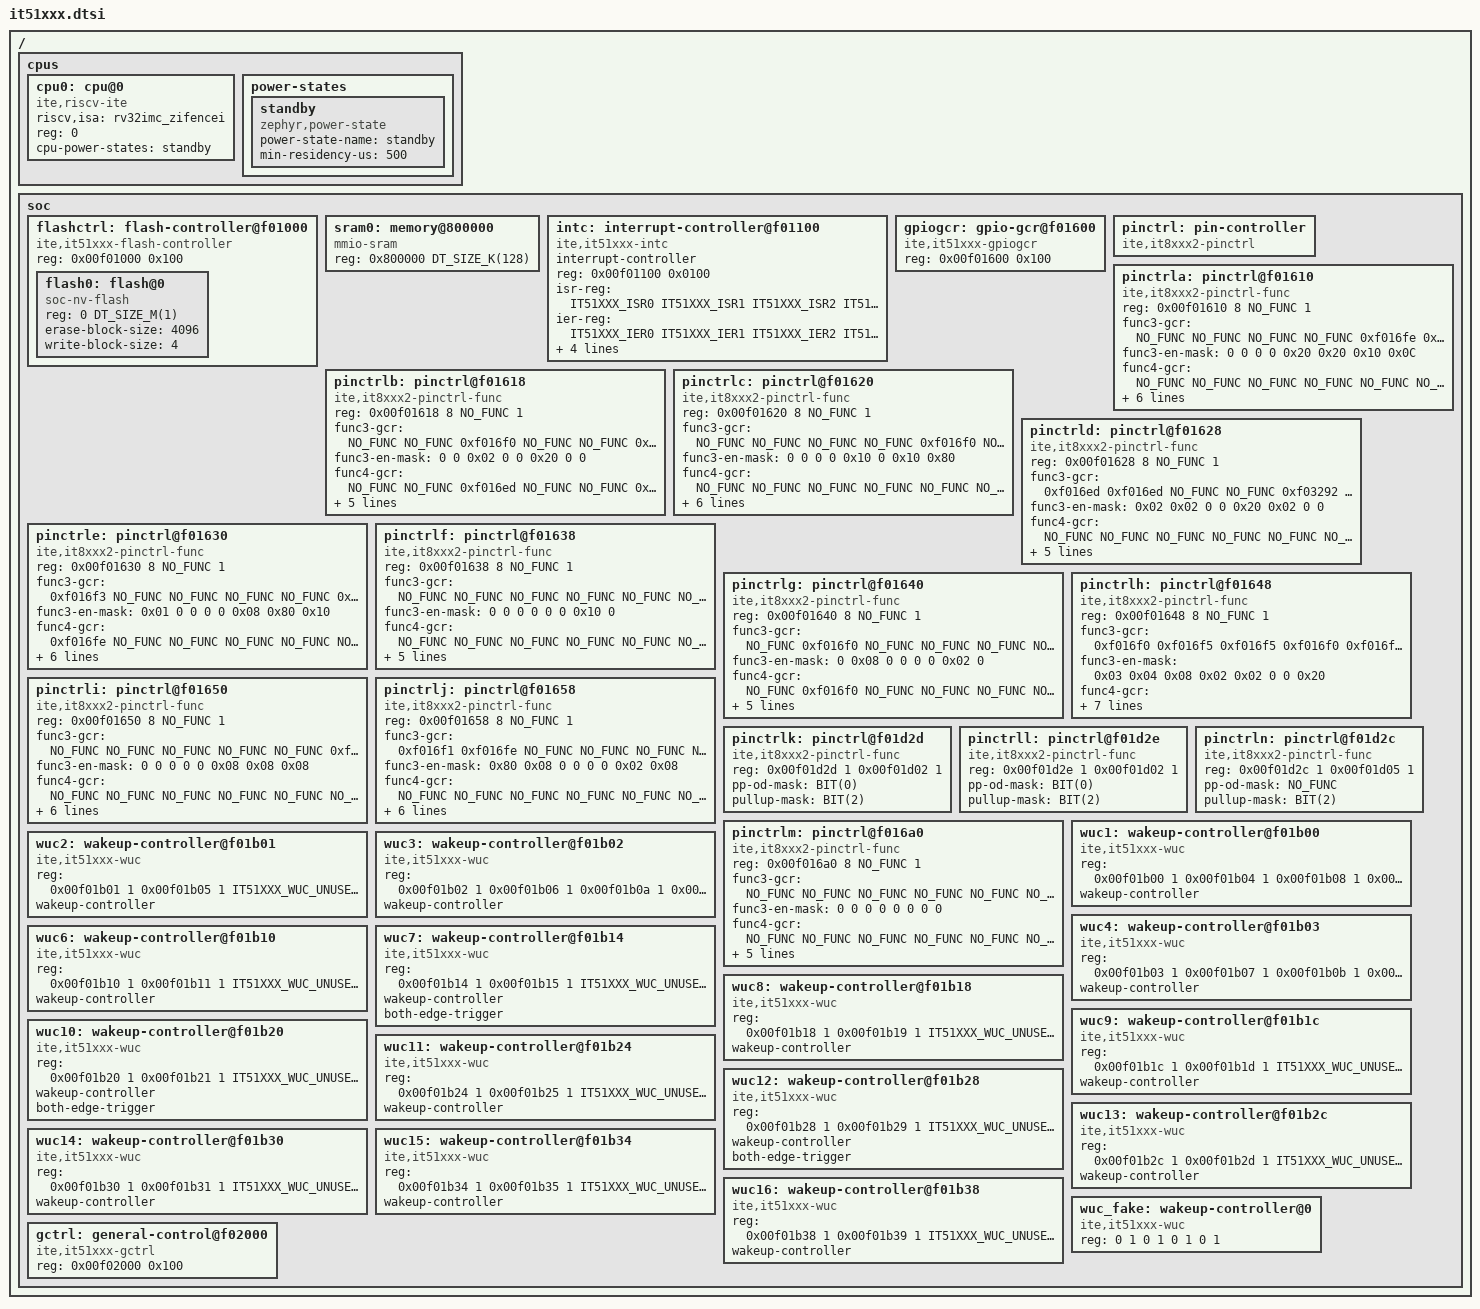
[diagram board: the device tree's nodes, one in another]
/*
 * Copyright (c) 2025 ITE Corporation. All Rights Reserved.
 *
 * SPDX-License-Identifier: Apache-2.0
 */

#include <ite/it51xxx-wuc-map.dtsi>
#include <mem.h>
#include <zephyr/dt-bindings/dt-util.h>
#include <zephyr/dt-bindings/interrupt-controller/ite-it51xxx-intc.h>
#include <zephyr/dt-bindings/interrupt-controller/ite-it51xxx-wuc.h>
#include <zephyr/dt-bindings/pinctrl/it8xxx2-pinctrl.h>

/ {
	#address-cells = <1>;
	#size-cells = <1>;

	cpus {
		#address-cells = <1>;
		#size-cells = <0>;
		cpu0: cpu@0 {
			compatible = "ite,riscv-ite", "riscv";
			riscv,isa = "rv32imc_zifencei";
			device_type = "cpu";
			reg = <0>;
			cpu-power-states = <&standby>;
		};

		power-states {
			standby: standby {
				compatible = "zephyr,power-state";
				power-state-name = "standby";
				min-residency-us = <500>;
			};
		};
	};

	soc {
		#address-cells = <1>;
		#size-cells = <1>;
		ranges;

		flashctrl: flash-controller@f01000 {
			compatible = "ite,it51xxx-flash-controller";
			reg = <0x00f01000 0x100>;
			#address-cells = <1>;
			#size-cells = <1>;

			flash0: flash@0 {
				compatible = "soc-nv-flash";
				reg = <0 DT_SIZE_M(1)>;
				erase-block-size = <4096>;
				write-block-size = <4>;
			};
		};

		sram0: memory@800000 {
			compatible = "mmio-sram";
			reg = <0x800000 DT_SIZE_K(128)>;
		};

		intc: interrupt-controller@f01100 {
			compatible = "ite,it51xxx-intc";
			#address-cells = <0>;
			#interrupt-cells = <2>;
			interrupt-controller;
			reg = <0x00f01100 0x0100>;
			isr-reg = <IT51XXX_ISR0  IT51XXX_ISR1  IT51XXX_ISR2  IT51XXX_ISR3
				   IT51XXX_ISR4  IT51XXX_ISR5  IT51XXX_ISR6  IT51XXX_ISR7
				   IT51XXX_ISR8  IT51XXX_ISR9  IT51XXX_ISR10 IT51XXX_ISR11
				   IT51XXX_ISR12 IT51XXX_ISR13 IT51XXX_ISR14 IT51XXX_ISR15
				   IT51XXX_ISR16 IT51XXX_ISR17 IT51XXX_ISR18 IT51XXX_ISR19
				   IT51XXX_ISR20 IT51XXX_ISR21 IT51XXX_ISR22 IT51XXX_ISR23
				   IT51XXX_ISR24 IT51XXX_ISR25>;
			ier-reg = <IT51XXX_IER0  IT51XXX_IER1  IT51XXX_IER2  IT51XXX_IER3
				   IT51XXX_IER4  IT51XXX_IER5  IT51XXX_IER6  IT51XXX_IER7
				   IT51XXX_IER8  IT51XXX_IER9  IT51XXX_IER10 IT51XXX_IER11
				   IT51XXX_IER12 IT51XXX_IER13 IT51XXX_IER14 IT51XXX_IER15
				   IT51XXX_IER16 IT51XXX_IER17 IT51XXX_IER18 IT51XXX_IER19
				   IT51XXX_IER20 IT51XXX_IER21 IT51XXX_IER22 IT51XXX_IER23
				   IT51XXX_IER24 IT51XXX_IER25>;
			ielmr-reg = <IT51XXX_IELMR0  IT51XXX_IELMR1  IT51XXX_IELMR2  IT51XXX_IELMR3
				     IT51XXX_IELMR4  IT51XXX_IELMR5  IT51XXX_IELMR6  IT51XXX_IELMR7
				     IT51XXX_IELMR8  IT51XXX_IELMR9  IT51XXX_IELMR10 IT51XXX_IELMR11
				     IT51XXX_IELMR12 IT51XXX_IELMR13 IT51XXX_IELMR14 IT51XXX_IELMR15
				     IT51XXX_IELMR16 IT51XXX_IELMR17 IT51XXX_IELMR18 IT51XXX_IELMR19
				     IT51XXX_IELMR20 IT51XXX_IELMR21 IT51XXX_IELMR22 IT51XXX_IELMR23
				      IT51XXX_IELMR24 IT51XXX_IELMR25>;
			ipolr-reg = <IT51XXX_IPOLR0  IT51XXX_IPOLR1  IT51XXX_IPOLR2  IT51XXX_IPOLR3
				     IT51XXX_IPOLR4  IT51XXX_IPOLR5  IT51XXX_IPOLR6  IT51XXX_IPOLR7
				     IT51XXX_IPOLR8  IT51XXX_IPOLR9  IT51XXX_IPOLR10 IT51XXX_IPOLR11
				     IT51XXX_IPOLR12 IT51XXX_IPOLR13 IT51XXX_IPOLR14 IT51XXX_IPOLR15
				     IT51XXX_IPOLR16 IT51XXX_IPOLR17 IT51XXX_IPOLR18 IT51XXX_IPOLR19
				     IT51XXX_IPOLR20 IT51XXX_IPOLR21 IT51XXX_IPOLR22 IT51XXX_IPOLR23
				     IT51XXX_IPOLR24 IT51XXX_IPOLR25>;
		};

		gpiogcr: gpio-gcr@f01600 {
			compatible = "ite,it51xxx-gpiogcr";
			reg = <0x00f01600 0x100>;
		};

		pinctrl: pin-controller {
			compatible = "ite,it8xxx2-pinctrl";
			#address-cells = <1>;
			#size-cells = <1>;
			status = "okay";
		};

		pinctrla: pinctrl@f01610 {
			compatible = "ite,it8xxx2-pinctrl-func";
			reg = <0x00f01610 8     /* GPCR */
			       NO_FUNC    1>;
			func3-gcr =     <NO_FUNC  NO_FUNC  NO_FUNC  NO_FUNC
					 0xf016fe 0xf016fe 0xf016f0 0xf016f0>;
			func3-en-mask = <0        0        0        0
					 0x20     0x20     0x10     0x0C    >;
			func4-gcr =     <NO_FUNC  NO_FUNC  NO_FUNC  NO_FUNC
					 NO_FUNC  NO_FUNC  NO_FUNC  NO_FUNC >;
			func4-en-mask = <0        0        0        0
					 0        0        0        0       >;
			volt-sel =      <0xf016d4 0xf016d4 0xf016d4 0xf016d4
					 NO_FUNC  NO_FUNC  0xf016d4 0xf016d4>;
			volt-sel-mask = <BIT(0)   BIT(1)   BIT(2)   BIT(3)
					 0        0        BIT(6)   BIT(7)  >;
			#pinmux-cells = <2>;
			gpio-group;
		};

		pinctrlb: pinctrl@f01618 {
			compatible = "ite,it8xxx2-pinctrl-func";
			reg = <0x00f01618 8     /* GPCR */
			       NO_FUNC    1>;
			func3-gcr =     <NO_FUNC  NO_FUNC  0xf016f0 NO_FUNC
					 NO_FUNC  0xf016f7 NO_FUNC  NO_FUNC >;
			func3-en-mask = <0        0        0x02     0
					 0        0x20     0        0       >;
			func4-gcr =     <NO_FUNC  NO_FUNC  0xf016ed NO_FUNC
					 NO_FUNC  0xf016ed NO_FUNC  NO_FUNC >;
			func4-en-mask = <0        0        0x04     0
					 0        0x08     0        0       >;
			volt-sel =      <NO_FUNC  NO_FUNC  0xf016d5 NO_FUNC
					 NO_FUNC  NO_FUNC  NO_FUNC  NO_FUNC >;
			volt-sel-mask = <0        0        BIT(2)   0
					 0        0        0        0       >;
			#pinmux-cells = <2>;
			gpio-group;
		};

		pinctrlc: pinctrl@f01620 {
			compatible = "ite,it8xxx2-pinctrl-func";
			reg = <0x00f01620 8     /* GPCR */
			       NO_FUNC    1>;
			func3-gcr =     <NO_FUNC  NO_FUNC  NO_FUNC  NO_FUNC
					 0xf016f0 NO_FUNC  0xf016f0 0xf016f6>;
			func3-en-mask = <0        0        0        0
					 0x10     0        0x10     0x80    >;
			func4-gcr =     <NO_FUNC  NO_FUNC  NO_FUNC  NO_FUNC
					 NO_FUNC  NO_FUNC  0xf016f4 0xf016f5>;
			func4-en-mask = <0        0        0        0
					 0        0        0x01     0x01    >;
			volt-sel =      <0xf016d6 NO_FUNC  NO_FUNC  0xf016d6
					 0xf016d6 0xf016d6 0xf016d6 NO_FUNC >;
			volt-sel-mask = <BIT(0)   0        0        BIT(3)
					 BIT(4)   BIT(5)   BIT(6)   0       >;
			#pinmux-cells = <2>;
			gpio-group;
		};

		pinctrld: pinctrl@f01628 {
			compatible = "ite,it8xxx2-pinctrl-func";
			reg = <0x00f01628 8     /* GPCR */
			       NO_FUNC    1>;
			func3-gcr =     <0xf016ed 0xf016ed NO_FUNC  NO_FUNC
					 0xf03292 0xf016f0 NO_FUNC  NO_FUNC >;
			func3-en-mask = <0x02     0x02     0        0
					 0x20     0x02     0        0       >;
			func4-gcr =     <NO_FUNC  NO_FUNC  NO_FUNC  NO_FUNC
					 NO_FUNC  NO_FUNC  NO_FUNC  NO_FUNC >;
			func4-en-mask = <0        0        0        0
					 0        0        0        0       >;
			volt-sel =      <NO_FUNC  NO_FUNC  NO_FUNC  NO_FUNC
					 NO_FUNC  0xf016d7 0xf016d7 0xf016d7>;
			volt-sel-mask = <0        0        0        0
					 0        BIT(5)   BIT(6)   BIT(7)  >;
			#pinmux-cells = <2>;
			gpio-group;
		};

		pinctrle: pinctrl@f01630 {
			compatible = "ite,it8xxx2-pinctrl-func";
			reg = <0x00f01630 8     /* GPCR */
			       NO_FUNC    1>;
			func3-gcr =     <0xf016f3 NO_FUNC  NO_FUNC  NO_FUNC
					 NO_FUNC  0xf016f0 0xf016fe 0xf016fe>;
			func3-en-mask = <0x01     0        0        0
					 0        0x08     0x80     0x10    >;
			func4-gcr =     <0xf016fe NO_FUNC  NO_FUNC  NO_FUNC
					 NO_FUNC  NO_FUNC  0xf016f5 NO_FUNC >;
			func4-en-mask = <0x10     0        0        0
					 0        0        0x02     0       >;
			volt-sel =      <NO_FUNC  0xf016d8 0xf016d8 0xf016d8
					 NO_FUNC  0xf016d8 NO_FUNC  NO_FUNC >;
			volt-sel-mask = <0        BIT(1)   BIT(2)   BIT(3)
					 0        BIT(5)   0        0       >;
			#pinmux-cells = <2>;
			gpio-group;
		};

		pinctrlf: pinctrl@f01638 {
			compatible = "ite,it8xxx2-pinctrl-func";
			reg = <0x00f01638 8     /* GPCR */
			       NO_FUNC    1>;
			func3-gcr =     <NO_FUNC  NO_FUNC  NO_FUNC  NO_FUNC
					 NO_FUNC  NO_FUNC  0xf016f1 NO_FUNC>;
			func3-en-mask = <0        0        0        0
					 0        0        0x10     0      >;
			func4-gcr =     <NO_FUNC  NO_FUNC  NO_FUNC  NO_FUNC
					 NO_FUNC  NO_FUNC  NO_FUNC  NO_FUNC>;
			func4-en-mask = <0        0        0        0
					 0        0        0        0      >;
			volt-sel =      <0xf016d9 0xf016d9 NO_FUNC  NO_FUNC
					 NO_FUNC  NO_FUNC  NO_FUNC  NO_FUNC>;
			volt-sel-mask = <BIT(0)   BIT(1)   0        0
					 0        0        0        0      >;
			#pinmux-cells = <2>;
			gpio-group;
		};

		pinctrlg: pinctrl@f01640 {
			compatible = "ite,it8xxx2-pinctrl-func";
			reg = <0x00f01640 8     /* GPCR */
			       NO_FUNC    1>;
			func3-gcr =     <NO_FUNC  0xf016f0 NO_FUNC  NO_FUNC
					 NO_FUNC  NO_FUNC  0xf016f0 NO_FUNC>;
			func3-en-mask = <0        0x08     0        0
					 0        0        0x02     0      >;
			func4-gcr =     <NO_FUNC  0xf016f0 NO_FUNC  NO_FUNC
					 NO_FUNC  NO_FUNC  NO_FUNC  NO_FUNC>;
			func4-en-mask = <0        0x40     0        0
					 0        0        0        0      >;
			volt-sel =      <0xf016da NO_FUNC  0xf016da NO_FUNC
					 NO_FUNC  NO_FUNC  NO_FUNC  NO_FUNC>;
			volt-sel-mask = <BIT(0)   0        BIT(2)   0
					 0        0        0        0      >;
			#pinmux-cells = <2>;
			gpio-group;
		};

		pinctrlh: pinctrl@f01648 {
			compatible = "ite,it8xxx2-pinctrl-func";
			reg = <0x00f01648 8     /* GPCR */
			       NO_FUNC    1>;
			func3-gcr =     <0xf016f0 0xf016f5 0xf016f5 0xf016f0
					 0xf016f0 NO_FUNC  NO_FUNC  0xf016f0>;
			func3-en-mask = <0x03     0x04     0x08     0x02
					 0x02     0        0        0x20    >;
			func4-gcr =     <0xf016ed 0xf016f1 0xf016f1 NO_FUNC
					 NO_FUNC  NO_FUNC  NO_FUNC  0xf016f5>;
			func4-en-mask = <0x04     0x20     0x20     0
					 0        0        0        0x80    >;
			volt-sel =      <NO_FUNC  NO_FUNC  NO_FUNC  0xf016db
					 0xf016db 0xf016db 0xf016db 0xf016db>;
			volt-sel-mask = <0        0        0        BIT(3)
					 BIT(4)   BIT(5)   BIT(6)   BIT(7)  >;
			#pinmux-cells = <2>;
			gpio-group;
		};

		pinctrli: pinctrl@f01650 {
			compatible = "ite,it8xxx2-pinctrl-func";
			reg = <0x00f01650 8     /* GPCR */
			       NO_FUNC    1>;
			func3-gcr =     <NO_FUNC  NO_FUNC  NO_FUNC  NO_FUNC
					 NO_FUNC  0xf016f0 0xf016f0 0xf016f0>;
			func3-en-mask = <0        0        0        0
					 0        0x08     0x08     0x08    >;
			func4-gcr =     <NO_FUNC  NO_FUNC  NO_FUNC  NO_FUNC
					 NO_FUNC  NO_FUNC  NO_FUNC  NO_FUNC >;
			func4-en-mask = <0        0        0        0
					 0        0        0        0       >;
			volt-sel =      <0xf016dc 0xf016dc 0xf016dc 0xf016dc
					 0xf016dc 0xf016dc 0xf016dc 0xf016dc>;
			volt-sel-mask = <BIT(0)   BIT(1)   BIT(2)   BIT(3)
					 BIT(4)   BIT(5)   BIT(6)   BIT(7)  >;
			#pinmux-cells = <2>;
			gpio-group;
		};

		pinctrlj: pinctrl@f01658 {
			compatible = "ite,it8xxx2-pinctrl-func";
			reg = <0x00f01658 8     /* GPCR */
			       NO_FUNC    1>;
			func3-gcr =     <0xf016f1 0xf016fe NO_FUNC  NO_FUNC
					 NO_FUNC  NO_FUNC  0xf016f4 0xf016d1>;
			func3-en-mask = <0x80     0x08     0        0
					 0        0        0x02     0x08    >;
			func4-gcr =     <NO_FUNC  NO_FUNC  NO_FUNC  NO_FUNC
					 NO_FUNC  NO_FUNC  0xf016ed 0xf016f0>;
			func4-en-mask = <0        0        0        0
					 0        0        0x08     0x10    >;
			volt-sel =      <0xf016dd NO_FUNC  0xf016dd 0xf016dd
					 0xf016dd 0xf016dd 0xf016dd 0xf016dd>;
			volt-sel-mask = <BIT(0)   0        BIT(2)   BIT(3)
					 BIT(4)   BIT(5)   BIT(6)   BIT(7)  >;
			#pinmux-cells = <2>;
			gpio-group;
		};

		pinctrlk: pinctrl@f01d2d {
			compatible = "ite,it8xxx2-pinctrl-func";
			reg = <0x00f01d2d 1   /* KSOLGCTRL */
			       0x00f01d02 1>; /* KSOCTRL */
			pp-od-mask = <BIT(0)>;
			pullup-mask = <BIT(2)>;
			#pinmux-cells = <2>;
		};

		pinctrll: pinctrl@f01d2e {
			compatible = "ite,it8xxx2-pinctrl-func";
			reg = <0x00f01d2e 1   /* KSOHGCTRL */
			       0x00f01d02 1>; /* KSOCTRL */
			pp-od-mask = <BIT(0)>;
			pullup-mask = <BIT(2)>;
			#pinmux-cells = <2>;
		};

		pinctrlm: pinctrl@f016a0 {
			compatible = "ite,it8xxx2-pinctrl-func";
			reg = <0x00f016a0 8     /* GPCR */
			       NO_FUNC    1>;
			func3-gcr =     <NO_FUNC NO_FUNC NO_FUNC NO_FUNC
					 NO_FUNC NO_FUNC NO_FUNC NO_FUNC>;
			func3-en-mask = <0       0       0       0
					 0       0       0       0      >;
			func4-gcr =     <NO_FUNC NO_FUNC NO_FUNC NO_FUNC
					 NO_FUNC NO_FUNC NO_FUNC NO_FUNC>;
			func4-en-mask = <0       0       0       0
					 0       0       0       0      >;
			volt-sel =      <NO_FUNC NO_FUNC NO_FUNC NO_FUNC
					 NO_FUNC NO_FUNC NO_FUNC NO_FUNC>;
			volt-sel-mask = <0       0       0       0
					 0       0       0       0      >;
			#pinmux-cells = <2>;
			gpio-group;
		};

		pinctrln: pinctrl@f01d2c {
			compatible = "ite,it8xxx2-pinctrl-func";
			reg = <0x00f01d2c 1   /* KSIGCTRL */
			       0x00f01d05 1>; /* KSICTRL */
			pp-od-mask = <NO_FUNC>;
			pullup-mask = <BIT(2)>;
			#pinmux-cells = <2>;
		};

		wuc1: wakeup-controller@f01b00 {
			compatible = "ite,it51xxx-wuc";
			reg = <0x00f01b00 1   /* WUEMR1 */
			       0x00f01b04 1   /* WUESR1 */
			       0x00f01b08 1   /* WUENR1 */
			       0x00f01b3c 1>; /* WUBEMR1 */
			wakeup-controller;
			#wuc-cells = <1>;
		};

		wuc2: wakeup-controller@f01b01 {
			compatible = "ite,it51xxx-wuc";
			reg = <0x00f01b01             1   /* WUEMR2 */
			       0x00f01b05             1   /* WUESR2 */
			       IT51XXX_WUC_UNUSED_REG 1   /* WUENR2 */
			       0x00f01b3d             1>; /* WUBEMR2 */
			wakeup-controller;
			#wuc-cells = <1>;
		};

		wuc3: wakeup-controller@f01b02 {
			compatible = "ite,it51xxx-wuc";
			reg = <0x00f01b02 1   /* WUEMR3 */
			       0x00f01b06 1   /* WUESR3 */
			       0x00f01b0a 1   /* WUENR3 */
			       0x00f01b3e 1>; /* WUBEMR3 */
			wakeup-controller;
			#wuc-cells = <1>;
		};

		wuc4: wakeup-controller@f01b03 {
			compatible = "ite,it51xxx-wuc";
			reg = <0x00f01b03 1   /* WUEMR4 */
			       0x00f01b07 1   /* WUESR4 */
			       0x00f01b0b 1   /* WUENR4 */
			       0x00f01b3f 1>; /* WUBEMR4 */
			wakeup-controller;
			#wuc-cells = <1>;
		};

		wuc6: wakeup-controller@f01b10 {
			compatible = "ite,it51xxx-wuc";
			reg = <0x00f01b10             1   /* WUEMR6 */
			       0x00f01b11             1   /* WUESR6 */
			       IT51XXX_WUC_UNUSED_REG 1   /* WUENR6 */
			       0x00f01b13             1>; /* WUBEMR6 */
			wakeup-controller;
			#wuc-cells = <1>;
		};

		wuc7: wakeup-controller@f01b14 {
			compatible = "ite,it51xxx-wuc";
			reg = <0x00f01b14             1   /* WUEMR7 */
			       0x00f01b15             1   /* WUESR7 */
			       IT51XXX_WUC_UNUSED_REG 1   /* WUENR7 */
			       0x00f01b17             1>; /* WUBEMR7 */
			wakeup-controller;
			both-edge-trigger;
			#wuc-cells = <1>;
		};

		wuc8: wakeup-controller@f01b18 {
			compatible = "ite,it51xxx-wuc";
			reg = <0x00f01b18             1   /* WUEMR8 */
			       0x00f01b19             1   /* WUESR8 */
			       IT51XXX_WUC_UNUSED_REG 1   /* WUENR8 */
			       0x00f01b1b             1>; /* WUBEMR8 */
			wakeup-controller;
			#wuc-cells = <1>;
		};

		wuc9: wakeup-controller@f01b1c {
			compatible = "ite,it51xxx-wuc";
			reg = <0x00f01b1c             1   /* WUEMR9 */
			       0x00f01b1d             1   /* WUESR9 */
			       IT51XXX_WUC_UNUSED_REG 1   /* WUENR9 */
			       0x00f01b1f             1>; /* WUBEMR9 */
			wakeup-controller;
			#wuc-cells = <1>;
		};

		wuc10: wakeup-controller@f01b20 {
			compatible = "ite,it51xxx-wuc";
			reg = <0x00f01b20             1   /* WUEMR10 */
			       0x00f01b21             1   /* WUESR10 */
			       IT51XXX_WUC_UNUSED_REG 1   /* WUENR10 */
			       0x00f01b23             1>; /* WUBEMR10 */
			wakeup-controller;
			both-edge-trigger;
			#wuc-cells = <1>;
		};

		wuc11: wakeup-controller@f01b24 {
			compatible = "ite,it51xxx-wuc";
			reg = <0x00f01b24             1   /* WUEMR11 */
			       0x00f01b25             1   /* WUESR11 */
			       IT51XXX_WUC_UNUSED_REG 1   /* WUENR11 */
			       0x00f01b27             1>; /* WUBEMR11 */
			wakeup-controller;
			#wuc-cells = <1>;
		};

		wuc12: wakeup-controller@f01b28 {
			compatible = "ite,it51xxx-wuc";
			reg = <0x00f01b28             1   /* WUEMR12 */
			       0x00f01b29             1   /* WUESR12 */
			       IT51XXX_WUC_UNUSED_REG 1   /* WUENR12 */
			       0x00f01b2b             1>; /* WUBEMR12 */
			wakeup-controller;
			both-edge-trigger;
			#wuc-cells = <1>;
		};

		wuc13: wakeup-controller@f01b2c {
			compatible = "ite,it51xxx-wuc";
			reg = <0x00f01b2c             1   /* WUEMR13 */
			       0x00f01b2d             1   /* WUESR13 */
			       IT51XXX_WUC_UNUSED_REG 1   /* WUENR13 */
			       0x00f01b2f             1>; /* WUBEMR13 */
			wakeup-controller;
			#wuc-cells = <1>;
		};

		wuc14: wakeup-controller@f01b30 {
			compatible = "ite,it51xxx-wuc";
			reg = <0x00f01b30             1   /* WUEMR14 */
			       0x00f01b31             1   /* WUESR14 */
			       IT51XXX_WUC_UNUSED_REG 1   /* WUENR14 */
			       0x00f01b33             1>; /* WUBEMR14 */
			wakeup-controller;
			#wuc-cells = <1>;
		};

		wuc15: wakeup-controller@f01b34 {
			compatible = "ite,it51xxx-wuc";
			reg = <0x00f01b34             1   /* WUEMR15 */
			       0x00f01b35             1   /* WUESR15 */
			       IT51XXX_WUC_UNUSED_REG 1   /* WUENR15 */
			       0x00f01b37             1>; /* WUBEMR15 */
			wakeup-controller;
			#wuc-cells = <1>;
		};

		wuc16: wakeup-controller@f01b38 {
			compatible = "ite,it51xxx-wuc";
			reg = <0x00f01b38             1   /* WUEMR16 */
			       0x00f01b39             1   /* WUESR16 */
			       IT51XXX_WUC_UNUSED_REG 1   /* WUENR16 */
			       0x00f01b3b             1>; /* WUBEMR16 */
			wakeup-controller;
			#wuc-cells = <1>;
		};

		wuc_fake: wakeup-controller@0 {
			compatible = "ite,it51xxx-wuc";
			reg = <0 1
			       0 1
			       0 1
			       0 1>;
			#wuc-cells = <1>;
		};

		gctrl: general-control@f02000 {
			compatible = "ite,it51xxx-gctrl";
			reg = <0x00f02000 0x100>;
		};

	};
};
